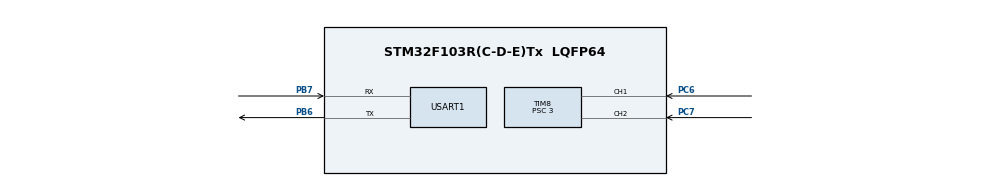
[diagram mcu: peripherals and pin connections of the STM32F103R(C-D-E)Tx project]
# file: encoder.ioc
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Dma.Request0=TIM8_CH3/UP
Dma.TIM8_CH3/UP.0.Direction=DMA_PERIPH_TO_MEMORY
Dma.TIM8_CH3/UP.0.Instance=DMA2_Channel1
Dma.TIM8_CH3/UP.0.MemDataAlignment=DMA_MDATAALIGN_WORD
Dma.TIM8_CH3/UP.0.MemInc=DMA_MINC_ENABLE
Dma.TIM8_CH3/UP.0.Mode=DMA_NORMAL
Dma.TIM8_CH3/UP.0.PeriphDataAlignment=DMA_PDATAALIGN_WORD
Dma.TIM8_CH3/UP.0.PeriphInc=DMA_PINC_DISABLE
Dma.TIM8_CH3/UP.0.Priority=DMA_PRIORITY_VERY_HIGH
Mcu.Family=STM32F1
Mcu.Name=STM32F103R(C-D-E)Tx
Mcu.Package=LQFP64
NVIC.DMA2_Channel1_IRQn=true\:0\:0\:false\:false\:true\:false\:true
NVIC.PriorityGroup=NVIC_PRIORITYGROUP_4
PA13.Mode=Serial_Wire
PA13.Signal=SYS_JTMS-SWDIO
PA14.Mode=Serial_Wire
PA14.Signal=SYS_JTCK-SWCLK
PB6.Mode=Asynchronous
PB6.Signal=USART1_TX
PB7.Mode=Asynchronous
PB7.Signal=USART1_RX
PC6.Signal=S_TIM8_CH1
PC7.Signal=S_TIM8_CH2
PD0-OSC_IN.Mode=HSE-External-Oscillator
PD0-OSC_IN.Signal=RCC_OSC_IN
PD1-OSC_OUT.Mode=HSE-External-Oscillator
PD1-OSC_OUT.Signal=RCC_OSC_OUT
ProjectManager.HeapSize=0x200
ProjectManager.StackSize=0x400
ProjectManager.TargetToolchain=EWARM V8
RCC.APB1Freq_Value=8000000
RCC.APB2Freq_Value=8000000
SH.S_TIM8_CH1.0=TIM8_CH1,Encoder_Interface
SH.S_TIM8_CH2.0=TIM8_CH2,Encoder_Interface
TIM8.AutoReloadPreload=TIM_AUTORELOAD_PRELOAD_ENABLE
TIM8.EncoderMode=TIM_ENCODERMODE_TI12
TIM8.IC1Filter=15
TIM8.IC2Filter=15
TIM8.Prescaler=3
USART1.VirtualMode=VM_ASYNC
board=custom

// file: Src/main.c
/* USER CODE BEGIN Header */
/**
  ******************************************************************************
  * @file           : main.c
  * @brief          : Main program body
  ******************************************************************************
  * @attention
  *
  * <h2><center>&copy; Copyright (c) 2019 STMicroelectronics.
  * All rights reserved.</center></h2>
  *
  * This software component is licensed by ST under BSD 3-Clause license,
  * the "License"; You may not use this file except in compliance with the
  * License. You may obtain a copy of the License at:
  *                        opensource.org/licenses/BSD-3-Clause
  *
  ******************************************************************************
  */
/* USER CODE END Header */

#include "main.h"
#include "stdio.h"

/* USER CODE BEGIN PTD */
#ifdef __GNUC__
  	#define PUTCHAR_PROTOTYPE 	int __io_putchar(int ch)
#else
  	#define PUTCHAR_PROTOTYPE 	int fputc(int ch, FILE *f)
#endif
/* USER CODE END PTD */

TIM_HandleTypeDef htim8;
DMA_HandleTypeDef hdma_tim8_ch3_up;

UART_HandleTypeDef huart1;
uint32_t cnt = 0;

void SystemClock_Config(void);
static void MX_GPIO_Init(void);
static void MX_DMA_Init(void);
static void MX_TIM8_Init(void);
static void MX_USART1_UART_Init(void);

/* USER CODE BEGIN 0 */

PUTCHAR_PROTOTYPE
{
  HAL_UART_Transmit(&huart1, (uint8_t *)&ch,1, 0xFFFF);
  return ch;
}
/* USER CODE END 0 */

int main(void)
{

  /* MCU Configuration--------------------------------------------------------*/

  /* Reset of all peripherals, Initializes the Flash interface and the Systick. */
  HAL_Init();

  /* Configure the system clock */
  SystemClock_Config();

  /* Initialize all configured peripherals */
  MX_GPIO_Init();
  MX_DMA_Init();
  MX_TIM8_Init();
  MX_USART1_UART_Init();

  /* Infinite loop */
  /* USER CODE BEGIN WHILE */

  printf("encoder demo\n");

  HAL_TIM_Encoder_Start(&htim8, TIM_CHANNEL_ALL);

  while (1)
  {
    /* USER CODE END WHILE */

    HAL_Delay(1000);

    cnt = (uint32_t)(__HAL_TIM_GET_COUNTER(&htim8));;

    printf("cnt:%d\n",cnt);

  }
}

void SystemClock_Config(void)
{
  RCC_OscInitTypeDef RCC_OscInitStruct = {0};
  RCC_ClkInitTypeDef RCC_ClkInitStruct = {0};

  /** Initializes the CPU, AHB and APB busses clocks
  */
  RCC_OscInitStruct.OscillatorType = RCC_OSCILLATORTYPE_HSI;
  RCC_OscInitStruct.HSIState = RCC_HSI_ON;
  RCC_OscInitStruct.HSICalibrationValue = RCC_HSICALIBRATION_DEFAULT;
  RCC_OscInitStruct.PLL.PLLState = RCC_PLL_NONE;
  if (HAL_RCC_OscConfig(&RCC_OscInitStruct) != HAL_OK)
  {
    Error_Handler();
  }
  /** Initializes the CPU, AHB and APB busses clocks
  */
  RCC_ClkInitStruct.ClockType = RCC_CLOCKTYPE_HCLK|RCC_CLOCKTYPE_SYSCLK
                              |RCC_CLOCKTYPE_PCLK1|RCC_CLOCKTYPE_PCLK2;
  RCC_ClkInitStruct.SYSCLKSource = RCC_SYSCLKSOURCE_HSI;
  RCC_ClkInitStruct.AHBCLKDivider = RCC_SYSCLK_DIV1;
  RCC_ClkInitStruct.APB1CLKDivider = RCC_HCLK_DIV1;
  RCC_ClkInitStruct.APB2CLKDivider = RCC_HCLK_DIV1;

  if (HAL_RCC_ClockConfig(&RCC_ClkInitStruct, FLASH_LATENCY_0) != HAL_OK)
  {
    Error_Handler();
  }
}

static void MX_TIM8_Init(void)
{

  TIM_Encoder_InitTypeDef sConfig = {0};
  TIM_MasterConfigTypeDef sMasterConfig = {0};

  htim8.Instance = TIM8;
  htim8.Init.Prescaler = 3;
  htim8.Init.CounterMode = TIM_COUNTERMODE_UP;
  htim8.Init.Period = 0xffffffff;
  htim8.Init.ClockDivision = TIM_CLOCKDIVISION_DIV1;
  htim8.Init.RepetitionCounter = 0;
  htim8.Init.AutoReloadPreload = TIM_AUTORELOAD_PRELOAD_DISABLE;
  sConfig.EncoderMode = TIM_ENCODERMODE_TI12;
  sConfig.IC1Polarity = TIM_ICPOLARITY_RISING;
  sConfig.IC1Selection = TIM_ICSELECTION_DIRECTTI;
  sConfig.IC1Prescaler = TIM_ICPSC_DIV1;
  sConfig.IC1Filter = 15;
  sConfig.IC2Polarity = TIM_ICPOLARITY_RISING;
  sConfig.IC2Selection = TIM_ICSELECTION_DIRECTTI;
  sConfig.IC2Prescaler = TIM_ICPSC_DIV1;
  sConfig.IC2Filter = 15;
  if (HAL_TIM_Encoder_Init(&htim8, &sConfig) != HAL_OK)
  {
    Error_Handler();
  }
  sMasterConfig.MasterOutputTrigger = TIM_TRGO_RESET;
  sMasterConfig.MasterSlaveMode = TIM_MASTERSLAVEMODE_DISABLE;
  if (HAL_TIMEx_MasterConfigSynchronization(&htim8, &sMasterConfig) != HAL_OK)
  {
    Error_Handler();
  }

}

static void MX_USART1_UART_Init(void)
{

  huart1.Instance = USART1;
  huart1.Init.BaudRate = 115200;
  huart1.Init.WordLength = UART_WORDLENGTH_8B;
  huart1.Init.StopBits = UART_STOPBITS_1;
  huart1.Init.Parity = UART_PARITY_NONE;
  huart1.Init.Mode = UART_MODE_TX_RX;
  huart1.Init.HwFlowCtl = UART_HWCONTROL_NONE;
  huart1.Init.OverSampling = UART_OVERSAMPLING_16;
  if (HAL_UART_Init(&huart1) != HAL_OK)
  {
    Error_Handler();
  }

}

static void MX_DMA_Init(void)
{

  /* DMA controller clock enable */
  __HAL_RCC_DMA2_CLK_ENABLE();

  /* DMA interrupt init */
  /* DMA2_Channel1_IRQn interrupt configuration */
  HAL_NVIC_SetPriority(DMA2_Channel1_IRQn, 0, 0);
  HAL_NVIC_EnableIRQ(DMA2_Channel1_IRQn);

}

static void MX_GPIO_Init(void)
{

  /* GPIO Ports Clock Enable */
  __HAL_RCC_GPIOD_CLK_ENABLE();
  __HAL_RCC_GPIOC_CLK_ENABLE();
  __HAL_RCC_GPIOA_CLK_ENABLE();

}

void Error_Handler(void)
{
}

/************************ (C) COPYRIGHT STMicroelectronics *****END OF FILE****/
